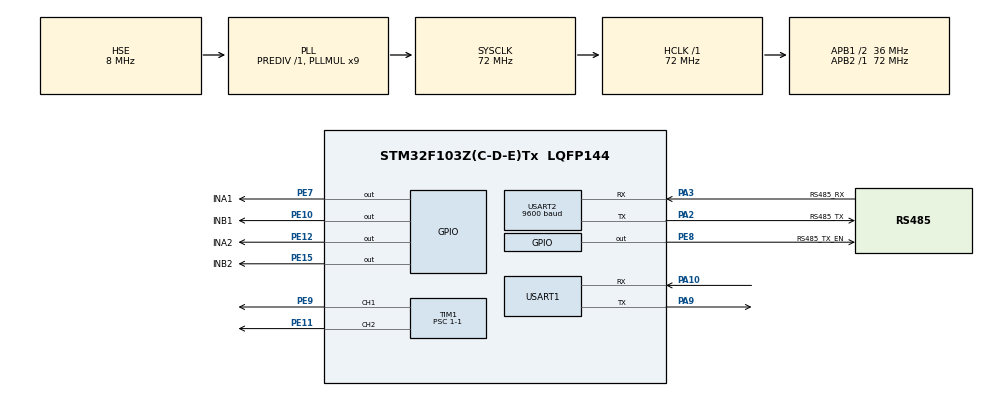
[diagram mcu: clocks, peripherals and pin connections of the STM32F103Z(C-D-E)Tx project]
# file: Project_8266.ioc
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Mcu.Family=STM32F1
Mcu.Name=STM32F103Z(C-D-E)Tx
Mcu.Package=LQFP144
NVIC.PriorityGroup=NVIC_PRIORITYGROUP_4
NVIC.USART1_IRQn=true\:1\:0\:true\:false\:true\:true\:true
NVIC.USART2_IRQn=true\:0\:0\:false\:false\:true\:true\:true
OSC_IN.Mode=HSE-External-Oscillator
OSC_IN.Signal=RCC_OSC_IN
OSC_OUT.Mode=HSE-External-Oscillator
OSC_OUT.Signal=RCC_OSC_OUT
PA10.Mode=Asynchronous
PA10.Signal=USART1_RX
PA13.Mode=JTAG_5_pins
PA13.Signal=SYS_JTMS-SWDIO
PA14.Mode=JTAG_5_pins
PA14.Signal=SYS_JTCK-SWCLK
PA15.Mode=JTAG_5_pins
PA15.Signal=SYS_JTDI
PA2.GPIO_Label=RS485_TX
PA2.Mode=Asynchronous
PA2.Signal=USART2_TX
PA3.GPIO_Label=RS485_RX
PA3.Mode=Asynchronous
PA3.Signal=USART2_RX
PA9.Mode=Asynchronous
PA9.Signal=USART1_TX
PB3.Mode=JTAG_5_pins
PB3.Signal=SYS_JTDO-TRACESWO
PB4.Mode=JTAG_5_pins
PB4.Signal=SYS_NJTRST
PE10.GPIO_Label=INB1
PE10.GPIO_Speed=GPIO_SPEED_FREQ_LOW
PE10.Signal=GPIO_Output
PE11.Signal=S_TIM1_CH2
PE12.GPIO_Label=INA2
PE12.Signal=GPIO_Output
PE15.GPIO_Label=INB2
PE15.Signal=GPIO_Output
PE7.GPIO_Label=INA1
PE7.Signal=GPIO_Output
PE8.GPIO_Label=RS485_TX_EN
PE8.GPIO_PuPd=GPIO_NOPULL
PE8.GPIO_Speed=GPIO_SPEED_FREQ_HIGH
PE8.Signal=GPIO_Output
PE9.Signal=S_TIM1_CH1
ProjectManager.HeapSize=0x200
ProjectManager.StackSize=0x400
ProjectManager.TargetToolchain=MDK-ARM V5.27
RCC.AHBFreq_Value=72000000
RCC.APB1CLKDivider=RCC_HCLK_DIV2
RCC.APB1Freq_Value=36000000
RCC.APB1TimFreq_Value=72000000
RCC.APB2Freq_Value=72000000
RCC.APB2TimFreq_Value=72000000
RCC.HCLKFreq_Value=72000000
RCC.PLLMUL=RCC_PLL_MUL9
RCC.PLLSourceVirtual=RCC_PLLSOURCE_HSE
RCC.SYSCLKFreq_VALUE=72000000
RCC.SYSCLKSource=RCC_SYSCLKSOURCE_PLLCLK
RCC.USBFreq_Value=72000000
SH.S_TIM1_CH1.0=TIM1_CH1,PWM Generation1 CH1
SH.S_TIM1_CH2.0=TIM1_CH2,PWM Generation2 CH2
TIM1.Channel-PWM\ Generation1\ CH1=TIM_CHANNEL_1
TIM1.Channel-PWM\ Generation2\ CH2=TIM_CHANNEL_2
TIM1.Period=1000-1
TIM1.Prescaler=1-1
TIM1.Pulse-PWM\ Generation1\ CH1=200
TIM1.Pulse-PWM\ Generation2\ CH2=200
USART1.VirtualMode=VM_ASYNC
USART2.BaudRate=9600
USART2.Parity=PARITY_EVEN
USART2.VirtualMode=VM_ASYNC
USART2.WordLength=WORDLENGTH_9B
VP_TIM1_VS_ClockSourceINT.Mode=Internal
board=custom

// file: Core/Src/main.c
/* USER CODE BEGIN Header */
/**
  ******************************************************************************
  * @file           : main.c
  * @brief          : Main program body
  ******************************************************************************
  * @attention
  *
  * <h2><center>&copy; Copyright (c) 2020 STMicroelectronics.
  * All rights reserved.</center></h2>
  *
  * This software component is licensed by ST under BSD 3-Clause license,
  * the "License"; You may not use this file except in compliance with the
  * License. You may obtain a copy of the License at:
  *                        opensource.org/licenses/BSD-3-Clause
  *
  ******************************************************************************
  */
/* USER CODE END Header */
#include "main.h"
#include "tim.h"
#include "usart.h"
#include "gpio.h"

/* USER CODE BEGIN Includes */

#include "string.h"
#include "esp8266.h"
#include "rs485.h"
#include "stm32f1xx_it.h"
#include  "data_processing.h"
#include "motor.h"

/* USER CODE END Includes */

/* USER CODE BEGIN PV */

uint8_t cmd2[5] = "12345";
extern uint8_t rx ;

/* USER CODE END PV */

void SystemClock_Config(void);

int main(void)
{

  /* MCU Configuration--------------------------------------------------------*/

  /* Reset of all peripherals, Initializes the Flash interface and the Systick. */
  HAL_Init();

  /* Configure the system clock */
  SystemClock_Config();

  /* Initialize all configured peripherals */
  MX_GPIO_Init();
  MX_USART1_UART_Init();
  MX_TIM1_Init();
  MX_USART2_UART_Init();
  /* USER CODE BEGIN 2 */

	ESP8266_Init();
	RS485_Init();

	HAL_TIM_PWM_Start(&htim1, TIM_CHANNEL_1);
	HAL_TIM_PWM_Start(&htim1, TIM_CHANNEL_2);
//	HAL_TIM_PWM_Start(&htim1, TIM_CHANNEL_3);
//	HAL_TIM_PWM_Start(&htim1, TIM_CHANNEL_4);

  /* USER CODE END 2 */

  /* Infinite loop */
	while (1)
  {

    /* USER CODE BEGIN 3 */
		HAL_Delay(10);
		All_status();
  }
  /* USER CODE END 3 */
}

void SystemClock_Config(void)
{
  RCC_OscInitTypeDef RCC_OscInitStruct = {0};
  RCC_ClkInitTypeDef RCC_ClkInitStruct = {0};

  /** Initializes the RCC Oscillators according to the specified parameters
  * in the RCC_OscInitTypeDef structure.
  */
  RCC_OscInitStruct.OscillatorType = RCC_OSCILLATORTYPE_HSE;
  RCC_OscInitStruct.HSEState = RCC_HSE_ON;
  RCC_OscInitStruct.HSEPredivValue = RCC_HSE_PREDIV_DIV1;
  RCC_OscInitStruct.HSIState = RCC_HSI_ON;
  RCC_OscInitStruct.PLL.PLLState = RCC_PLL_ON;
  RCC_OscInitStruct.PLL.PLLSource = RCC_PLLSOURCE_HSE;
  RCC_OscInitStruct.PLL.PLLMUL = RCC_PLL_MUL9;
  if (HAL_RCC_OscConfig(&RCC_OscInitStruct) != HAL_OK)
  {
    Error_Handler();
  }
  /** Initializes the CPU, AHB and APB buses clocks
  */
  RCC_ClkInitStruct.ClockType = RCC_CLOCKTYPE_HCLK|RCC_CLOCKTYPE_SYSCLK
                              |RCC_CLOCKTYPE_PCLK1|RCC_CLOCKTYPE_PCLK2;
  RCC_ClkInitStruct.SYSCLKSource = RCC_SYSCLKSOURCE_PLLCLK;
  RCC_ClkInitStruct.AHBCLKDivider = RCC_SYSCLK_DIV1;
  RCC_ClkInitStruct.APB1CLKDivider = RCC_HCLK_DIV2;
  RCC_ClkInitStruct.APB2CLKDivider = RCC_HCLK_DIV1;

  if (HAL_RCC_ClockConfig(&RCC_ClkInitStruct, FLASH_LATENCY_2) != HAL_OK)
  {
    Error_Handler();
  }
}

void Error_Handler(void)
{
}

/************************ (C) COPYRIGHT STMicroelectronics *****END OF FILE****/
